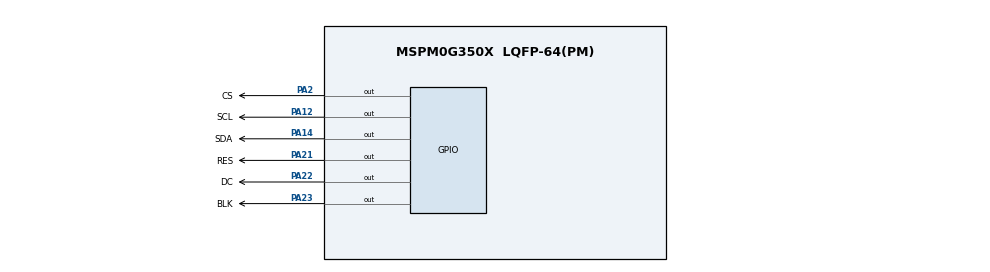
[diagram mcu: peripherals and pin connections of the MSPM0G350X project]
/**
 * @cliArgs --device "MSPM0G350X" --part "Default" --package "LQFP-64(PM)" --product "mspm0_sdk@2.10.00.04"
 * @versions {"tool":"1.27.0+4565"}
 */

/**
 * Import the modules used in this configuration.
 */
const GPIO   = scripting.addModule("/ti/driverlib/GPIO", {}, false);
const GPIO1  = GPIO.addInstance();
const SYSCTL = scripting.addModule("/ti/driverlib/SYSCTL");

/**
 * Write custom configuration values to the imported modules.
 */
GPIO1.$name                          = "GPIO";
GPIO1.port                           = "PORTA";
GPIO1.associatedPins.create(6);
GPIO1.associatedPins[0].$name        = "SCL";
GPIO1.associatedPins[0].initialValue = "SET";
GPIO1.associatedPins[0].assignedPin  = "12";
GPIO1.associatedPins[0].pin.$assign  = "PA12";
GPIO1.associatedPins[1].$name        = "SDA";
GPIO1.associatedPins[1].initialValue = "SET";
GPIO1.associatedPins[1].assignedPin  = "14";
GPIO1.associatedPins[1].pin.$assign  = "PA14";
GPIO1.associatedPins[2].$name        = "RES";
GPIO1.associatedPins[2].assignedPin  = "21";
GPIO1.associatedPins[2].initialValue = "SET";
GPIO1.associatedPins[2].pin.$assign  = "PA21";
GPIO1.associatedPins[3].$name        = "DC";
GPIO1.associatedPins[3].initialValue = "SET";
GPIO1.associatedPins[3].assignedPin  = "22";
GPIO1.associatedPins[3].pin.$assign  = "PA22";
GPIO1.associatedPins[4].$name        = "CS";
GPIO1.associatedPins[4].assignedPin  = "2";
GPIO1.associatedPins[4].initialValue = "SET";
GPIO1.associatedPins[4].pin.$assign  = "PA2";
GPIO1.associatedPins[5].$name        = "BLK";
GPIO1.associatedPins[5].initialValue = "SET";
GPIO1.associatedPins[5].assignedPin  = "23";
GPIO1.associatedPins[5].pin.$assign  = "PA23";

const Board = scripting.addModule("/ti/driverlib/Board", {}, false);

SYSCTL.forceDefaultClkConfig = true;

/**
 * Pinmux solution for unlocked pins/peripherals. This ensures that minor changes to the automatic solver in a future
 * version of the tool will not impact the pinmux you originally saw.  These lines can be completely deleted in order to
 * re-solve from scratch.
 */
Board.peripheral.$suggestSolution          = "DEBUGSS";
Board.peripheral.swclkPin.$suggestSolution = "PA20";
Board.peripheral.swdioPin.$suggestSolution = "PA19";
SYSCTL.peripheral.$suggestSolution         = "SYSCTL";
